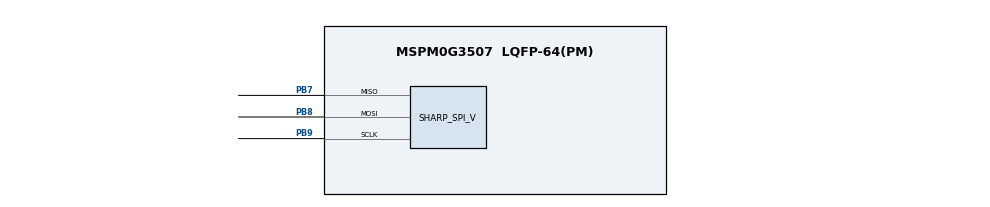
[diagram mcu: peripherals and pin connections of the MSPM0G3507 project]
//@cliArgs --device "MSPM0G350X" --package "LQFP-64(PM)" --part "Default"
//@v2CliArgs --device "MSPM0G3507" --package "LQFP-64(PM)"
// @cliArgs --board /ti/boards/LP_MSPM0G3507 --rtos nortos
// BOOSTXL-SHARP128 on the LP-MSPM0G3507. Generated by boards/gen_syscfg.py; edit the table there.
// SPI mode 0, MSB first, 8-bit frames, 1 MHz (the panel's rate); chip selects are plain GPIO.
const GPIO   = scripting.addModule("/ti/driverlib/GPIO", {}, false);
const SPI    = scripting.addModule("/ti/driverlib/SPI", {}, false);
const Board  = scripting.addModule("/ti/driverlib/Board", {}, false);
const SYSCTL = scripting.addModule("/ti/driverlib/SYSCTL", {}, false);
const SHARP_SPI_V = SPI.addInstance();

const g_pwr = GPIO.addInstance();
g_pwr.$name = "GP_PWR";
g_pwr.port  = "PORTA";
g_pwr.associatedPins[0].$name = "PIN_PWR";
g_pwr.associatedPins[0].assignedPin = "25";
const g_disp = GPIO.addInstance();
g_disp.$name = "GP_DISP";
g_disp.port  = "PORTA";
g_disp.associatedPins[0].$name = "PIN_DISP";
g_disp.associatedPins[0].assignedPin = "26";
const g_lcs = GPIO.addInstance();
g_lcs.$name = "GP_LCD_CS";
g_lcs.port  = "PORTB";
g_lcs.associatedPins[0].$name = "PIN_LCD_CS";
g_lcs.associatedPins[0].assignedPin = "24";
const g_scs = GPIO.addInstance();
g_scs.$name = "GP_SD_CS";
g_scs.port  = "PORTA";
g_scs.associatedPins[0].$name = "PIN_SD_CS";
g_scs.associatedPins[0].assignedPin = "27";
g_scs.associatedPins[0].initialValue = "SET";
const g_det = GPIO.addInstance();
g_det.$name = "GP_SD_DET";
g_det.port  = "PORTB";
g_det.associatedPins[0].$name = "PIN_SD_DET";
g_det.associatedPins[0].assignedPin = "15";
g_det.associatedPins[0].direction = "INPUT";
g_det.associatedPins[0].internalResistor = "PULL_UP";

SHARP_SPI_V.$name                      = "SHARP_SPI";
SHARP_SPI_V.targetBitRate              = 1000000;
SHARP_SPI_V.frameFormat                = "MOTO3";
SHARP_SPI_V.peripheral.$assign         = "SPI1";
SHARP_SPI_V.peripheral.sclkPin.$assign = "PB9";
SHARP_SPI_V.peripheral.mosiPin.$assign = "PB8";
SHARP_SPI_V.peripheral.misoPin.$assign = "PB7";

SYSCTL.forceDefaultClkConfig = true;
SYSCTL.clockTreeEn           = true;
